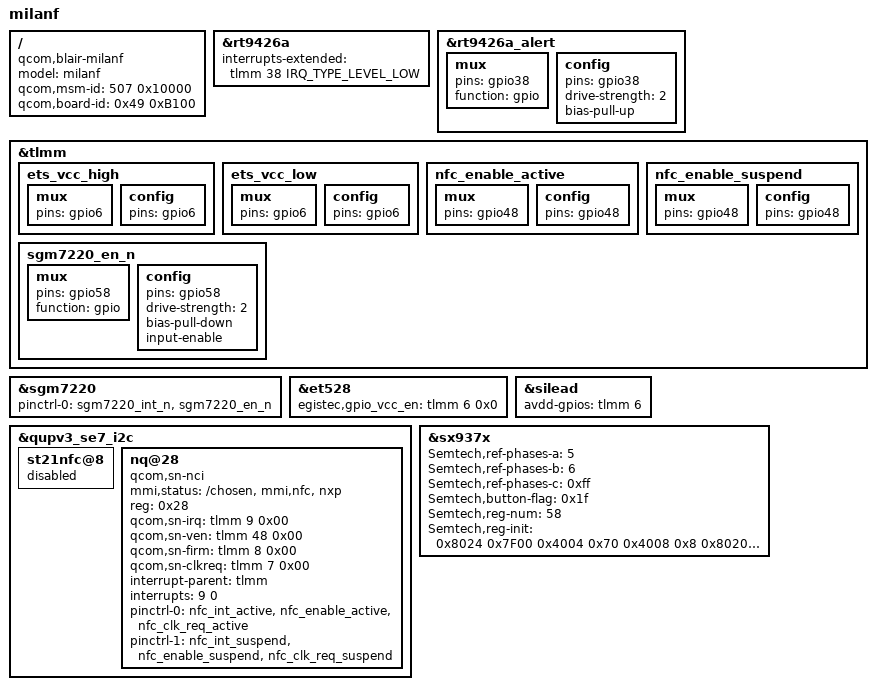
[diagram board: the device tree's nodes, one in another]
/* Copyright (c) 2021, The Linux Foundation. All rights reserved.
 *
 * This program is free software; you can redistribute it and/or modify
 * it under the terms of the GNU General Public License version 2 and
 * only version 2 as published by the Free Software Foundation.
 *
 * This program is distributed in the hope that it will be useful,
 * but WITHOUT ANY WARRANTY; without even the implied warranty of
 * MERCHANTABILITY or FITNESS FOR A PARTICULAR PURPOSE.  See the
 * GNU General Public License for more details.
 */

/dts-v1/;
/plugin/;

#include "blair-nopmi-milanf-common-overlay.dtsi"

/ {
	model = "milanf";
	compatible = "qcom,blair-milanf", "qcom,blair-moto", "qcom,blair";
	qcom,msm-id = <507 0x10000>;
	qcom,board-id = <0x49 0xB100>;
};

&rt9426a {
	interrupts-extended = <&tlmm 38 IRQ_TYPE_LEVEL_LOW>;
};
&rt9426a_alert {
	mux {
		pins = "gpio38";
		function = "gpio";
	};

	config {
		pins = "gpio38";
		drive-strength = <2>;
		bias-pull-up;
	};
};

&tlmm {
	ets_vcc_high {
		mux {
			pins = "gpio6";
		};

		config {
			pins = "gpio6";
		};
	};

	ets_vcc_low {
		mux {
			pins = "gpio6";
		};

		config {
			pins = "gpio6";
		};
	};

	nfc_enable_active {
		mux {
			pins = "gpio48";
		};

		config {
			pins = "gpio48";
		};
	};

	nfc_enable_suspend {
		mux {
			pins = "gpio48";
		};

		config {
			pins = "gpio48";
		};
	};

	sgm7220_en_n: sgm7220_en_n {
		mux {
			pins = "gpio58";
			function = "gpio";
		};

		config {
			pins = "gpio58";
			drive-strength = <2>;
			bias-pull-down;
			input-enable;
		};
	};
};

&sgm7220 {
	pinctrl-names = "default";
	pinctrl-0 = <&sgm7220_int_n &sgm7220_en_n>;
};

&et528 {
	egistec,gpio_vcc_en = <&tlmm 6 0x0>;
};

&silead {
	avdd-gpios = <&tlmm 6 0x0>;
};

&qupv3_se7_i2c {
	st21nfc@8 {
		status = "diabled";
	};

	nq@28 {
		compatible = "qcom,sn-nci";
		mmi,status = "/chosen", "mmi,nfc", "nxp";
		reg = <0x28>;
		qcom,sn-irq = <&tlmm 9 0x00>;
		qcom,sn-ven = <&tlmm 48 0x00>;
		qcom,sn-firm = <&tlmm 8 0x00>;
		qcom,sn-clkreq = <&tlmm 7 0x00>;
		interrupt-parent = <&tlmm>;
		interrupts = <9 0>;
		interrupt-names = "nfc_irq";
		pinctrl-names = "nfc_active", "nfc_suspend";
		pinctrl-0 = <&nfc_int_active &nfc_enable_active
				&nfc_clk_req_active>;
		pinctrl-1 = <&nfc_int_suspend &nfc_enable_suspend
				&nfc_clk_req_suspend>;
	};
};

&sx937x {
	Semtech,ref-phases-a = <5>;
	Semtech,ref-phases-b = <6>;
	Semtech,ref-phases-c = <0xff>;
	Semtech,button-flag = <0x1f>;
	Semtech,reg-num = <58>;
	Semtech,reg-init = <
		0x8024  0x7F00
		0x4004  0x70
		0x4008  0x8
		0x8020  0x32
		0x8028  0x886 		/*AFE_PARAM_PH0*/
		0x8034  0x886 		/*AFE_PARAM_PH1*/
		0x8040  0x886 		/*AFE_PARAM_PH2*/
		0x804C  0x8BE    	/*AFE_PARAM_PH3*/
		0x8058  0x866 		/*AFE_PARAM_PH4*/
		0x8064  0x86E 		/*AFE_PARAM_PH5*/
		0x8070  0x86E 		/*AFE_PARAM_PH6*/
		0x807C  0x85E  		/*AFE_PARAM_PH7*/
		/*set CS3 to hiz, because it used as IRQ pin*/
		0x8030  0xFFF9FD 	/*REG_AFEPH_PH0, CS0, ANT1, Bottom center*/
		0x803C  0xFFD9FF 	/*REG_AFEPH_PH1, CS4, ANT2, Top right*/
		0x8048  0xFEF9FF 	/*REG_AFEPH_PH2, CS5, ANT7, Bottom Right*/
		0x8054  0xF7F9FF	/*REG_AFEPH_PH3, CS6, ANT4, Top Right*/
		0x8060  0xFFF97F 	/*REG_AFEPH_PH4, CS2, ANT5, Top center*/
		0x806C  0xFFF9EF 	/*REG_AFEPH_PH5, CS1, ANT1/7_REF, Bottom_Ref*/
		0x8078  0xBFF9FF 	/*REG_AFEPH_PH6, CS7, ANT4 REF, Middle*/
		0x8084  0xFFF9FF 	/*REG_AFEPH_PH7, NOT USE*/
		0x8098  0x7A36
		0x80B8  0x7636
		0x80D8  0x5959
		0x80F8  0x3939
		0x8118  0x2C2C
		0x8138  0xFF
		0x8158  0xFF
		0x8178  0x5A40
		0x80A0  0x1E1E00E1
		0x80C0  0x404000E2
		0x80E0  0x222200E1
		0x8100  0x161600E2
		0x8188  0x8000015
		0x818C  0x8000016
		0x8090  0x41DB3000
		0x80B0  0x7FB33000
		0x80D0  0x40CD3000
		0x80F0  0x68BD3000
		0x8110  0x30DD3000
		0x8130  0x2AD67000
		0x8150  0x2AD67000
		0x8170  0x2AD67000
		0x8088  0x300005
		0x80A8  0x300005
		0x80C8  0x300005
		0x80E8  0x300005
		0x8108  0x300005
		0x8128  0x3600000
		0x8148  0x3600000
		0x8168  0x300000
		0x808C  0x60200060
		0x80AC  0x60200060
		0x80CC  0x60200060
		0x80EC  0x60200060
		0x810C  0x60200060
		0x812C  0x60200018
		0x814C  0x60200018
		0x816C  0x60200018
	>;

	status = "ok";
};
